# R7KA8D2AD register map
Vendor: Renesas Electronics Corporation; Series: RA8; File version: 1.10.02
CPU: CM85 r0p2, little endian, MPU, FPU, VTOR, 4 interrupt priority bits, 96 interrupts
Registers are 32-bit, read-write, reset 0x0 unless marked. A register's access mark holds for its fields unless they carry their own. Offsets are from the block's base; [hi:lo] are bit positions; {n}, {i} and the like mark numbered series; <NAME> marks a mode.

## DOC_B — Data Operation Circuit
Base 0x40311000
Same registers: DOC_B_NS 0x50311000
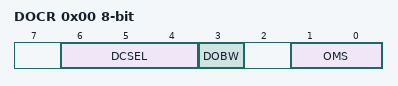
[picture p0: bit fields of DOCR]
0x00 DOCR 8-bit — DOC Control Register
  [6:4] DCSEL — Detection Condition Select
    0=Mismatch (DODSR0 ≠ DODIR); 1=Match (DODSR0 = DODIR); 2=Lower (DODSR0 > DODIR); 3=Upper (DODSR0 < DODIR); 4=Inside window (DODSR0 < DODIR < DODSR1); 5=Outside window (DODIR < DODSR0, DODSR1 < DODIR); other=Others (Setting prohibited)
  [3] DOBW — Data Operation Bit Width Select
    0=16-bit; 1=32-bit
  [1:0] OMS — Operating Mode Select
    0=Data comparison mode; 1=Data addition mode; 2=Data subtraction mode; 3=Setting prohibited
0x04 DOSR 8-bit ro — DOC Flag Status Register
  [0] DOPCF — Data Operation Circuit Flag
0x08 DOSCR 8-bit wo — DOC Flag Status Clear Register
  [0] DOPCFCL — DOPCF Clear
    0=Maintains the DOPCF flag state; 1=Clears the DOPCF flag
0x0C DODIR — DOC Data Input Register
0x10 DODSR0 — DOC Data Setting Register 0
0x14 DODSR1 — DOC Data Setting Register 1

## GPT_OPS — Output Phase Switching Controller
Base 0x40323F00
Same registers: GPT_OPS_NS 0x50323F00
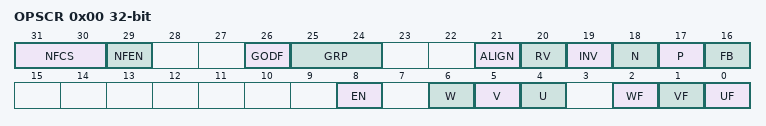
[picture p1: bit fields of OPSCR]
0x00 OPSCR — Output Phase Switching Control Register
  [31:30] NFCS — External Input Noise Filter Clock Selection
    0=GTCLK/1; 1=GTCLK/4; 2=GTCLK/16; 3=GTCLK/64
  [29] NFEN — External Input Noise Filter Enable
    0=Do not use a noise filter on the external input; 1=Use a noise filter on the external input
  [26] GODF — Group Output Disable Function
    0=This bit function is ignored; 1=Group disable clears the OPSCR.EN bit
  [25:24] GRP — Output Disabled Source Selection
  [21] ALIGN — Input Phase Alignment
    0=Input phase aligned to GTCLK; 1=Input phase aligned to the falling edge of PWM
  [20] RV — Output Phase Rotation Direction Reversal Control
    0=Positive rotation; 1=Reverse rotation
  [19] INV — Output Phase Invert Control
    0=Positive logic (active-high) output; 1=Negative logic (active-low) output
  [18] N — Negative-Phase Output (N) Control
    0=Level signal output; 1=PWM signal output
  [17] P — Positive-Phase Output (P) Control
    0=Level signal output; 1=PWM signal output
  [16] FB — External Feedback Signal Enable
    0=Select the external input; 1=Select the soft setting (OPSCR.UF, VF, WF)
  [8] EN — Output Phase Enable
    0=Do not output (Hi-Z external pin); 1=Output
  [6] W ro — Input W-Phase Monitor
  [5] V ro — Input V-Phase Monitor
  [4] U ro — Input U-Phase Monitor
  [2] WF
  [1] VF
  [0] UF

## GPT_GTCLK — General PWM Timer Clock Controller
Base 0x40323F10
Same registers: GPT_GTCLK_NS 0x50323F10
0x00 GTCLKCR — General PWM Timer Clock Control Register
  [0] BPEN — Synchronization Circuit Bypass Enable
    0=In case of using Bus Clock and GPT Core Clock asynchronously; 1=In case of using Bus Clock and GPT Core Clock synchronously

## PDG — PWM Delay Generation Circuit
Base 0x40324000
Same registers: PDG_NS 0x50324000
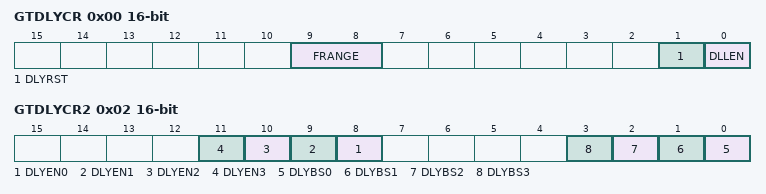
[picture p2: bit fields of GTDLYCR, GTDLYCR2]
0x00 GTDLYCR 16-bit — PWM Output Delay Control Register
  [9:8] FRANGE — GPT core clock Frequency Range
    0=GPT core clock frequency is 80 MHz to 160 MHz; 1=GPT core clock frequency is 155 MHz to 300 MHz; other=Others (Setting prohibited)
  [1] DLYRST — PWM Delay Generation Circuit Reset
    0=Normal operation; 1=Reset
  [0] DLLEN — DLL Operation Enable
    0=DLL operation disabled; 1=DLL operation enabled
0x02 GTDLYCR2 16-bit — PWM Output Delay Control Register 2
  [n+8] DLYEN{n} (n=0..3) — PWM Delay Generation Circuit enable for channel {n}
    0=Delay generation circuit of channel {n} enabled; 1=Delay generation circuit of channel {n} disabled
  [n] DLYBS{n} (n=0..3) — PWM Delay Generation Circuit bypass for channel {n}
    0=Delay generation circuit of channel {n} bypassed; 1=Delay generation circuit of channel {n} not bypassed
{0x18+4i} GTDLYR{i}A (i=0..3) 16-bit — GTIOCnA Rising Output Delay Register
  [6:0] DLY — GTIOCnA Output Rising Edge Delay Setting
{0x1A+4i} GTDLYR{i}B (i=0..3) 16-bit — GTIOCnB Rising Output Delay Register
  [6:0] DLY — GTIOCnB Output Rising Edge Delay Setting
{0x28+4i} GTDLYF{i}A (i=0..3) 16-bit — GTIOCnA Falling Output Delay Register
  [6:0] DLY — GTIOCnA Output Falling Edge Delay Setting
{0x2A+4i} GTDLYF{i}B (i=0..3) 16-bit — GTIOCnB Falling Output Delay Register
  [6:0] DLY — GTIOCnB Output Falling Edge Delay Setting
